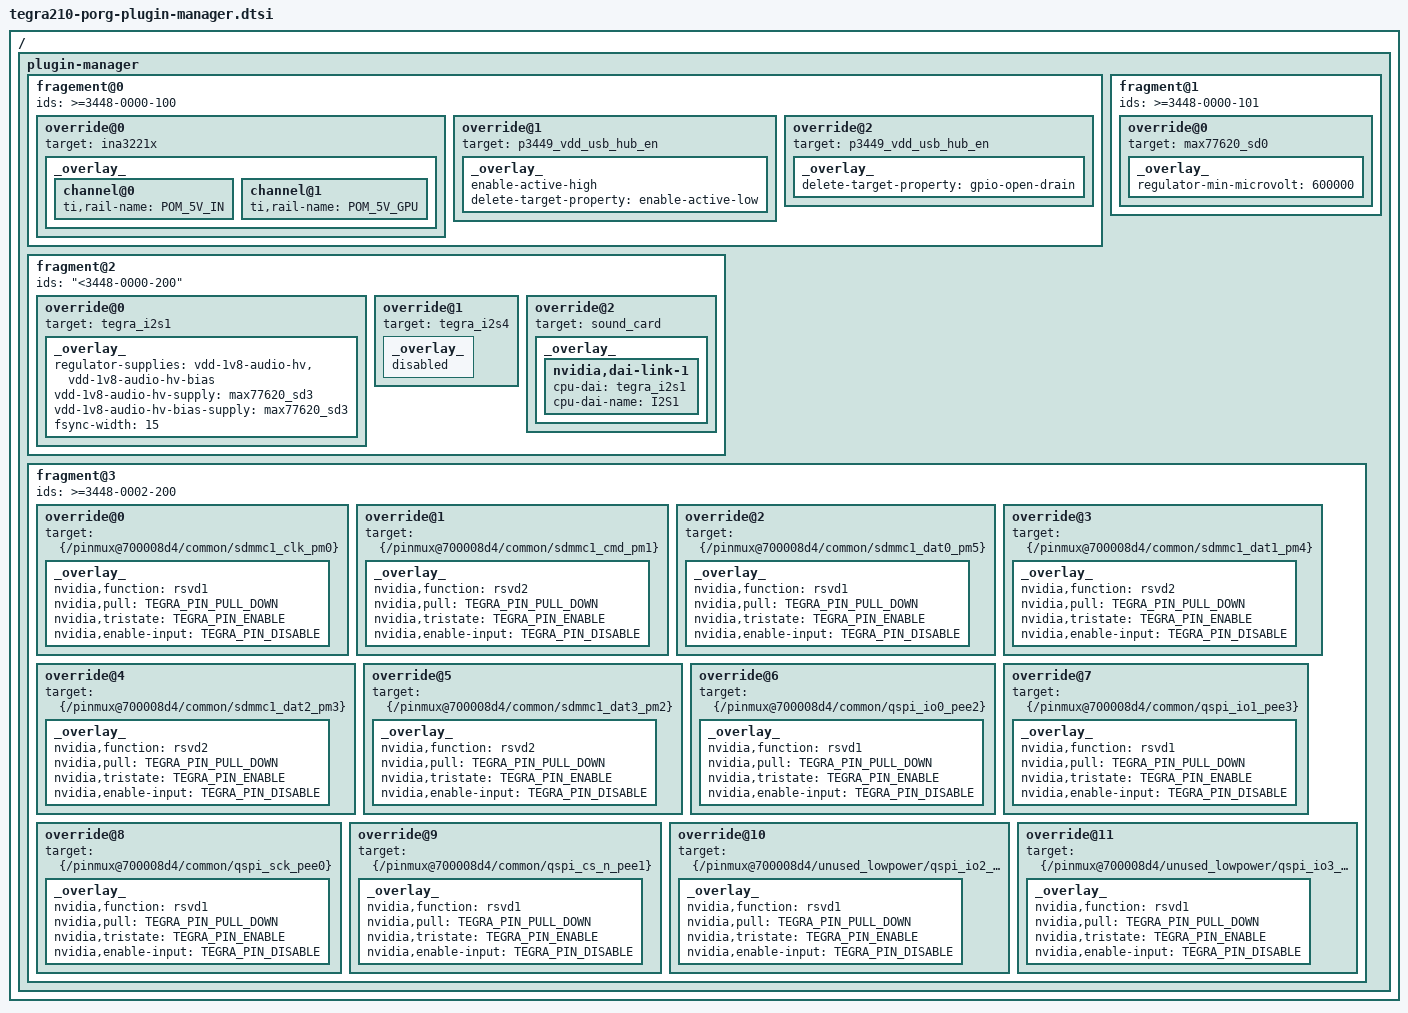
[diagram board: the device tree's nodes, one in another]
/*
 * Copyright (c) 2019, NVIDIA CORPORATION.  All rights reserved.
 *
 * This program is free software; you can redistribute it and/or modify
 * it under the terms of the GNU General Public License as published by
 * the Free Software Foundation; version 2 of the License.
 *
 * This program is distributed in the hope that it will be useful, but WITHOUT
 * ANY WARRANTY; without even the implied warranty of MERCHANTABILITY or
 * FITNESS FOR A PARTICULAR PURPOSE.  See the GNU General Public License for
 * more details.
 *
 */

/ {
	plugin-manager {
		fragement@0 {
			ids = ">=3448-0000-100";
			override@0 {
				target = <&ina3221x>;
				_overlay_ {
					channel@0 {
						ti,rail-name = "POM_5V_IN";
					};
					channel@1 {
						ti,rail-name = "POM_5V_GPU";
					};
				};
			};

			override@1 {
				target = <&p3449_vdd_usb_hub_en>;
				_overlay_ {
					enable-active-high;
					delete-target-property = "enable-active-low";
				};
			};

			override@2 {
				target = <&p3449_vdd_usb_hub_en>;
				_overlay_ {
					delete-target-property = "gpio-open-drain";
				};
			};
		};

		fragment@1 {
			ids = ">=3448-0000-101";
			override@0 {
				target = <&max77620_sd0>;
				_overlay_ {
					regulator-min-microvolt = <600000>;
				};
			};
		};

		fragment@2 {
			ids = "<3448-0000-200";
			override@0 {
				target = <&tegra_i2s1>;
				_overlay_ {
					regulator-supplies = "vdd-1v8-audio-hv", "vdd-1v8-audio-hv-bias";
					vdd-1v8-audio-hv-supply = <&max77620_sd3>;
					vdd-1v8-audio-hv-bias-supply = <&max77620_sd3>;
					fsync-width = <15>;
					status = "okay";
				};
			};

			override@1 {
				target = <&tegra_i2s4>;
				_overlay_ {
					status = "disabled";
				};
			};

			override@2 {
				target = <&sound_card>;
				_overlay_ {
					nvidia,dai-link-1 {
						cpu-dai = <&tegra_i2s1>;
						cpu-dai-name = "I2S1";
					};
				};
			};
		};

		fragment@3 {
			ids = ">=3448-0002-200";
			override@0 {
				target = <&{/pinmux@700008d4/common/sdmmc1_clk_pm0}>;
				_overlay_ {
					nvidia,function = "rsvd1";
					nvidia,pull = <TEGRA_PIN_PULL_DOWN>;
					nvidia,tristate = <TEGRA_PIN_ENABLE>;
					nvidia,enable-input = <TEGRA_PIN_DISABLE>;
				};
			};

			override@1 {
				target = <&{/pinmux@700008d4/common/sdmmc1_cmd_pm1}>;
				_overlay_ {
					nvidia,function = "rsvd2";
					nvidia,pull = <TEGRA_PIN_PULL_DOWN>;
					nvidia,tristate = <TEGRA_PIN_ENABLE>;
					nvidia,enable-input = <TEGRA_PIN_DISABLE>;
				};
			};

			override@2 {
				target = <&{/pinmux@700008d4/common/sdmmc1_dat0_pm5}>;
				_overlay_ {
					nvidia,function = "rsvd1";
					nvidia,pull = <TEGRA_PIN_PULL_DOWN>;
					nvidia,tristate = <TEGRA_PIN_ENABLE>;
					nvidia,enable-input = <TEGRA_PIN_DISABLE>;
				};
			};

			override@3 {
				target = <&{/pinmux@700008d4/common/sdmmc1_dat1_pm4}>;
				_overlay_ {
					nvidia,function = "rsvd2";
					nvidia,pull = <TEGRA_PIN_PULL_DOWN>;
					nvidia,tristate = <TEGRA_PIN_ENABLE>;
					nvidia,enable-input = <TEGRA_PIN_DISABLE>;
				};
			};

			override@4 {
				target = <&{/pinmux@700008d4/common/sdmmc1_dat2_pm3}>;
				_overlay_ {
					nvidia,function = "rsvd2";
					nvidia,pull = <TEGRA_PIN_PULL_DOWN>;
					nvidia,tristate = <TEGRA_PIN_ENABLE>;
					nvidia,enable-input = <TEGRA_PIN_DISABLE>;
				};
			};

			override@5 {
				target = <&{/pinmux@700008d4/common/sdmmc1_dat3_pm2}>;
				_overlay_ {
					nvidia,function = "rsvd2";
					nvidia,pull = <TEGRA_PIN_PULL_DOWN>;
					nvidia,tristate = <TEGRA_PIN_ENABLE>;
					nvidia,enable-input = <TEGRA_PIN_DISABLE>;
				};
			};

			override@6 {
				target = <&{/pinmux@700008d4/common/qspi_io0_pee2}>;
				_overlay_ {
					nvidia,function = "rsvd1";
					nvidia,pull = <TEGRA_PIN_PULL_DOWN>;
					nvidia,tristate = <TEGRA_PIN_ENABLE>;
					nvidia,enable-input = <TEGRA_PIN_DISABLE>;
				};
			};

			override@7 {
				target = <&{/pinmux@700008d4/common/qspi_io1_pee3}>;
				_overlay_ {
					nvidia,function = "rsvd1";
					nvidia,pull = <TEGRA_PIN_PULL_DOWN>;
					nvidia,tristate = <TEGRA_PIN_ENABLE>;
					nvidia,enable-input = <TEGRA_PIN_DISABLE>;
				};
			};

			override@8 {
				target = <&{/pinmux@700008d4/common/qspi_sck_pee0}>;
				_overlay_ {
					nvidia,function = "rsvd1";
					nvidia,pull = <TEGRA_PIN_PULL_DOWN>;
					nvidia,tristate = <TEGRA_PIN_ENABLE>;
					nvidia,enable-input = <TEGRA_PIN_DISABLE>;
				};
			};

			override@9 {
				target = <&{/pinmux@700008d4/common/qspi_cs_n_pee1}>;
				_overlay_ {
					nvidia,function = "rsvd1";
					nvidia,pull = <TEGRA_PIN_PULL_DOWN>;
					nvidia,tristate = <TEGRA_PIN_ENABLE>;
					nvidia,enable-input = <TEGRA_PIN_DISABLE>;
				};
			};

			override@10 {
				target = <&{/pinmux@700008d4/unused_lowpower/qspi_io2_pee4}>;
				_overlay_ {
					nvidia,function = "rsvd1";
					nvidia,pull = <TEGRA_PIN_PULL_DOWN>;
					nvidia,tristate = <TEGRA_PIN_ENABLE>;
					nvidia,enable-input = <TEGRA_PIN_DISABLE>;
				};
			};

			override@11 {
				target = <&{/pinmux@700008d4/unused_lowpower/qspi_io3_pee5}>;
				_overlay_ {
					nvidia,function = "rsvd1";
					nvidia,pull = <TEGRA_PIN_PULL_DOWN>;
					nvidia,tristate = <TEGRA_PIN_ENABLE>;
					nvidia,enable-input = <TEGRA_PIN_DISABLE>;
				};
			};
		};
	};
};
